VERSION ""

NS_ :

BS_:

BU_: DEWESoft

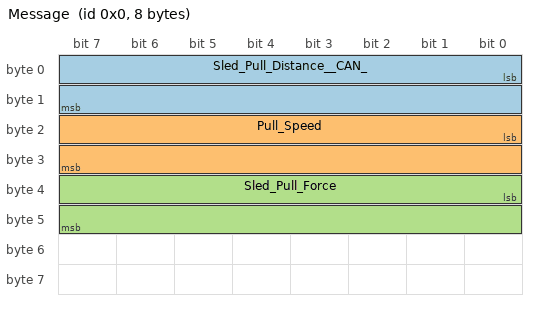
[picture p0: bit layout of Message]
BO_ 0 Message: 8 DEWESoft
 SG_ Sled_Pull_Distance__CAN_ : 0|16@1+ (0.01,0) [0|65535] "ft"  DEWESoft
 SG_ Pull_Speed : 16|16@1+ (0.1,0) [0|65535] "mph"  DEWESoft
 SG_ Sled_Pull_Force : 32|16@1+ (1,0) [0|65535] "lbf"  DEWESoft

CM_ SG_ 0 Sled_Pull_Distance__CAN_ "-";
CM_ SG_ 0 Pull_Speed "-";
CM_ SG_ 0 Sled_Pull_Force "-";
BA_DEF_ SG_  "DEWESoft_Sig_Name" STRING ;
BA_DEF_DEF_  "DEWESoft_Sig_Name" "";
BA_ "DEWESoft_Sig_Name" SG_ 0 Sled_Pull_Distance__CAN_ "Sled Pull Distance (CAN)";
BA_ "DEWESoft_Sig_Name" SG_ 0 Pull_Speed "Pull Speed";
BA_ "DEWESoft_Sig_Name" SG_ 0 Sled_Pull_Force "Sled Pull Force";
